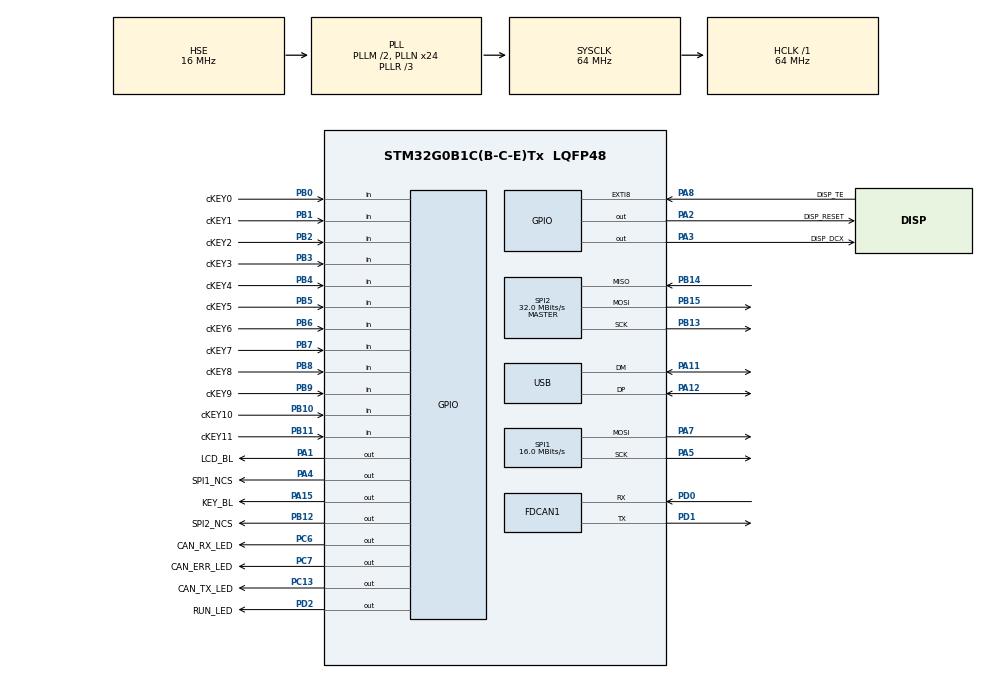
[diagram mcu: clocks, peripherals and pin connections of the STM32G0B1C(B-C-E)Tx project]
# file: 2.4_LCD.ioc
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Dma.Request0=SPI1_TX
Dma.Request1=SPI2_RX
Dma.Request2=SPI2_TX
Dma.SPI1_TX.0.Direction=DMA_MEMORY_TO_PERIPH
Dma.SPI1_TX.0.EventEnable=DISABLE
Dma.SPI1_TX.0.Instance=DMA1_Channel1
Dma.SPI1_TX.0.MemDataAlignment=DMA_MDATAALIGN_HALFWORD
Dma.SPI1_TX.0.MemInc=DMA_MINC_ENABLE
Dma.SPI1_TX.0.Mode=DMA_NORMAL
Dma.SPI1_TX.0.PeriphDataAlignment=DMA_PDATAALIGN_HALFWORD
Dma.SPI1_TX.0.PeriphInc=DMA_PINC_DISABLE
Dma.SPI1_TX.0.Polarity=HAL_DMAMUX_REQ_GEN_RISING
Dma.SPI1_TX.0.Priority=DMA_PRIORITY_HIGH
Dma.SPI1_TX.0.RequestNumber=1
Dma.SPI1_TX.0.SignalID=NONE
Dma.SPI1_TX.0.SyncEnable=DISABLE
Dma.SPI1_TX.0.SyncPolarity=HAL_DMAMUX_SYNC_NO_EVENT
Dma.SPI1_TX.0.SyncRequestNumber=1
Dma.SPI1_TX.0.SyncSignalID=NONE
Dma.SPI2_RX.1.Direction=DMA_PERIPH_TO_MEMORY
Dma.SPI2_RX.1.EventEnable=DISABLE
Dma.SPI2_RX.1.Instance=DMA1_Channel2
Dma.SPI2_RX.1.MemDataAlignment=DMA_MDATAALIGN_BYTE
Dma.SPI2_RX.1.MemInc=DMA_MINC_ENABLE
Dma.SPI2_RX.1.Mode=DMA_NORMAL
Dma.SPI2_RX.1.PeriphDataAlignment=DMA_PDATAALIGN_BYTE
Dma.SPI2_RX.1.PeriphInc=DMA_PINC_DISABLE
Dma.SPI2_RX.1.Polarity=HAL_DMAMUX_REQ_GEN_RISING
Dma.SPI2_RX.1.Priority=DMA_PRIORITY_VERY_HIGH
Dma.SPI2_RX.1.RequestNumber=1
Dma.SPI2_RX.1.SignalID=NONE
Dma.SPI2_RX.1.SyncEnable=DISABLE
Dma.SPI2_RX.1.SyncPolarity=HAL_DMAMUX_SYNC_NO_EVENT
Dma.SPI2_RX.1.SyncRequestNumber=1
Dma.SPI2_RX.1.SyncSignalID=NONE
Dma.SPI2_TX.2.Direction=DMA_MEMORY_TO_PERIPH
Dma.SPI2_TX.2.EventEnable=DISABLE
Dma.SPI2_TX.2.Instance=DMA1_Channel3
Dma.SPI2_TX.2.MemDataAlignment=DMA_MDATAALIGN_BYTE
Dma.SPI2_TX.2.MemInc=DMA_MINC_ENABLE
Dma.SPI2_TX.2.Mode=DMA_NORMAL
Dma.SPI2_TX.2.PeriphDataAlignment=DMA_PDATAALIGN_BYTE
Dma.SPI2_TX.2.PeriphInc=DMA_PINC_DISABLE
Dma.SPI2_TX.2.Polarity=HAL_DMAMUX_REQ_GEN_RISING
Dma.SPI2_TX.2.Priority=DMA_PRIORITY_MEDIUM
Dma.SPI2_TX.2.RequestNumber=1
Dma.SPI2_TX.2.SignalID=NONE
Dma.SPI2_TX.2.SyncEnable=DISABLE
Dma.SPI2_TX.2.SyncPolarity=HAL_DMAMUX_SYNC_NO_EVENT
Dma.SPI2_TX.2.SyncRequestNumber=1
Dma.SPI2_TX.2.SyncSignalID=NONE
FDCAN1.AutoRetransmission=ENABLE
FDCAN1.CalculateBaudRateNominal=500000
FDCAN1.CalculateTimeBitNominal=2000
FDCAN1.CalculateTimeQuantumNominal=62.5
FDCAN1.DataPrescaler=1
FDCAN1.NominalPrescaler=4
FDCAN1.NominalSyncJumpWidth=4
FDCAN1.NominalTimeSeg1=27
FDCAN1.NominalTimeSeg2=4
FDCAN1.StdFiltersNbr=1
Mcu.Family=STM32G0
Mcu.Name=STM32G0B1C(B-C-E)Tx
Mcu.Package=LQFP48
NVIC.DMA1_Channel1_IRQn=true\:0\:0\:false\:false\:true\:false\:true\:true
NVIC.DMA1_Channel2_3_IRQn=true\:0\:0\:false\:false\:true\:false\:true\:true
NVIC.EXTI4_15_IRQn=true\:0\:0\:false\:false\:true\:true\:true\:true
NVIC.TIM16_FDCAN_IT0_IRQn=true\:0\:0\:false\:false\:true\:true\:true\:true
NVIC.USB_UCPD1_2_IRQn=true\:0\:0\:false\:false\:true\:true\:true\:true
PA1.GPIO_Label=LCD_BL
PA1.Signal=GPIO_Output
PA11\ [PA9].Mode=Device
PA11\ [PA9].Signal=USB_DM
PA12\ [PA10].Mode=Device
PA12\ [PA10].Signal=USB_DP
PA13.Mode=Serial_Wire
PA13.Signal=SYS_SWDIO
PA14-BOOT0.Mode=Serial_Wire
PA14-BOOT0.Signal=SYS_SWCLK
PA15.GPIO_Label=KEY_BL
PA15.PinState=GPIO_PIN_RESET
PA15.Signal=GPIO_Output
PA2.GPIO_Label=DISP_RESET
PA2.PinState=GPIO_PIN_SET
PA2.Signal=GPIO_Output
PA3.GPIO_Label=DISP_DCX
PA3.GPIO_Speed=GPIO_SPEED_FREQ_VERY_HIGH
PA3.Signal=GPIO_Output
PA4.GPIO_Label=SPI1_NCS
PA4.GPIO_Speed=GPIO_SPEED_FREQ_VERY_HIGH
PA4.PinState=GPIO_PIN_SET
PA4.Signal=GPIO_Output
PA5.GPIO_Speed=GPIO_SPEED_FREQ_VERY_HIGH
PA5.Mode=TX_Only_Simplex_Unidirect_Master
PA5.PinState=GPIO_PIN_RESET
PA5.Signal=SPI1_SCK
PA7.GPIO_Speed=GPIO_SPEED_FREQ_VERY_HIGH
PA7.Mode=TX_Only_Simplex_Unidirect_Master
PA7.Signal=SPI1_MOSI
PA8.GPIO_Label=DISP_TE
PA8.Signal=GPXTI8
PB0.GPIO_Label=cKEY0
PB0.Signal=GPIO_Input
PB1.GPIO_Label=cKEY1
PB1.Signal=GPIO_Input
PB10.GPIO_Label=cKEY10
PB10.Signal=GPIO_Input
PB11.GPIO_Label=cKEY11
PB11.Signal=GPIO_Input
PB12.GPIO_Label=SPI2_NCS
PB12.GPIO_Speed=GPIO_SPEED_FREQ_VERY_HIGH
PB12.PinState=GPIO_PIN_SET
PB12.Signal=GPIO_Output
PB13.GPIO_Speed=GPIO_SPEED_FREQ_VERY_HIGH
PB13.Mode=Full_Duplex_Master
PB13.Signal=SPI2_SCK
PB14.Mode=Full_Duplex_Master
PB14.Signal=SPI2_MISO
PB15.GPIO_Speed=GPIO_SPEED_FREQ_VERY_HIGH
PB15.Mode=Full_Duplex_Master
PB15.Signal=SPI2_MOSI
PB2.GPIO_Label=cKEY2
PB2.Signal=GPIO_Input
PB3.GPIO_Label=cKEY3
PB3.Signal=GPIO_Input
PB4.GPIO_Label=cKEY4
PB4.Signal=GPIO_Input
PB5.GPIO_Label=cKEY5
PB5.Signal=GPIO_Input
PB6.GPIO_Label=cKEY6
PB6.Signal=GPIO_Input
PB7.GPIO_Label=cKEY7
PB7.Signal=GPIO_Input
PB8.GPIO_Label=cKEY8
PB8.Signal=GPIO_Input
PB9.GPIO_Label=cKEY9
PB9.Signal=GPIO_Input
PC13.GPIO_Label=CAN_TX_LED
PC13.PinState=GPIO_PIN_SET
PC13.Signal=GPIO_Output
PC6.GPIO_Label=CAN_RX_LED
PC6.PinState=GPIO_PIN_SET
PC6.Signal=GPIO_Output
PC7.GPIO_Label=CAN_ERR_LED
PC7.PinState=GPIO_PIN_SET
PC7.Signal=GPIO_Output
PD0.Mode=FDCAN_Activate
PD0.Signal=FDCAN1_RX
PD1.Mode=FDCAN_Activate
PD1.Signal=FDCAN1_TX
PD2.GPIO_Label=RUN_LED
PD2.PinState=GPIO_PIN_SET
PD2.Signal=GPIO_Output
PF0-OSC_IN\ (PF0).Mode=HSE-External-Oscillator
PF0-OSC_IN\ (PF0).Signal=RCC_OSC_IN
PF1-OSC_OUT\ (PF1).Mode=HSE-External-Oscillator
PF1-OSC_OUT\ (PF1).Signal=RCC_OSC_OUT
ProjectManager.HeapSize=0x200
ProjectManager.StackSize=0x800
ProjectManager.TargetToolchain=CMake
RCC.ADCFreq_Value=64000000
RCC.AHBFreq_Value=64000000
RCC.CortexFreq_Value=64000000
RCC.EXTERNAL_CLOCK_VALUE=48000
RCC.HCLKFreq_Value=64000000
RCC.HSE_VALUE=16000000
RCC.HSI48_VALUE=48000000
RCC.HSI_VALUE=16000000
RCC.LSE_VALUE=32768
RCC.PLLM=RCC_PLLM_DIV2
RCC.PLLN=24
RCC.PLLQ=RCC_PLLQ_DIV4
RCC.PLLR=RCC_PLLR_DIV3
RCC.PLLSourceVirtual=RCC_PLLSOURCE_HSE
RCC.SYSCLKFreq_VALUE=64000000
RCC.SYSCLKSource=RCC_SYSCLKSOURCE_PLLCLK
RCC.USBCLockSelection=RCC_USBCLKSOURCE_PLL
RCC.USBFreq_Value=48000000
RCC.VCOOutputFreq_Value=192000000
SPI1.BaudRatePrescaler=SPI_BAUDRATEPRESCALER_4
SPI1.CalculateBaudRate=16.0 MBits/s
SPI1.DataSize=SPI_DATASIZE_8BIT
SPI1.Direction=SPI_DIRECTION_2LINES
SPI1.Mode=SPI_MODE_MASTER
SPI1.VirtualType=VM_MASTER
SPI2.BaudRatePrescaler=SPI_BAUDRATEPRESCALER_2
SPI2.CalculateBaudRate=32.0 MBits/s
SPI2.DataSize=SPI_DATASIZE_8BIT
SPI2.Direction=SPI_DIRECTION_2LINES
SPI2.Mode=SPI_MODE_MASTER
SPI2.VirtualType=VM_MASTER
STMicroelectronics.X-CUBE-TOUCHGFX.4.26.1.ApplicationCcGraphicsJjApplication=TouchGFXOoGenerator
STMicroelectronics.X-CUBE-TOUCHGFX.4.26.1.tgfx_block_size=9600
STMicroelectronics.X-CUBE-TOUCHGFX.4.26.1.tgfx_buffering_strategy=Partial
STMicroelectronics.X-CUBE-TOUCHGFX.4.26.1.tgfx_custom_height=320
STMicroelectronics.X-CUBE-TOUCHGFX.4.26.1.tgfx_custom_width=240
STMicroelectronics.X-CUBE-TOUCHGFX.4.26.1.tgfx_datareader=Enabled
STMicroelectronics.X-CUBE-TOUCHGFX.4.26.1.tgfx_datareader_dma_transfersize=16
STMicroelectronics.X-CUBE-TOUCHGFX.4.26.1.tgfx_datareader_mem_size=0x00800000
STMicroelectronics.X-CUBE-TOUCHGFX.4.26.1.tgfx_number_of_blocks=2
STMicroelectronics.X-CUBE-TOUCHGFX.4.26.1_IsPackSelfContextualization=true
USB_DEVICE.CLASS_NAME_FS=CDC
USB_DEVICE.VirtualMode=Cdc
USB_DEVICE.VirtualModeFS=Cdc_FS
VP_CRC_VS_CRC.Mode=CRC_Activate
VP_STMicroelectronics.X-CUBE-TOUCHGFX_VS_GraphicsJjApplication_4.26.1.Mode=GraphicsJjApplication
VP_SYS_VS_DBSignals.Mode=DisableDeadBatterySignals
VP_USB_DEVICE_VS_USB_DEVICE_CDC_FS.Mode=CDC_FS
board=custom

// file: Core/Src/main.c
/* USER CODE BEGIN Header */
/**
  ******************************************************************************
  * @file           : main.c
  * @brief          : Main program body
  ******************************************************************************
  * @attention
  *
  * Copyright (c) 2026 STMicroelectronics.
  * All rights reserved.
  *
  * This software is licensed under terms that can be found in the LICENSE file
  * in the root directory of this software component.
  * If no LICENSE file comes with this software, it is provided AS-IS.
  *
  ******************************************************************************
  */
/* USER CODE END Header */
#include "main.h"
#include "crc.h"
#include "dma.h"
#include "fdcan.h"
#include "spi.h"
#include "usb_device.h"
#include "gpio.h"
#include "app_touchgfx.h"

/* USER CODE BEGIN Includes */
#include <stdio.h>
#include "dbg_console.h"
#include "display_driver.h"
#include "flash_driver.h"
#include "app_main.h"
/* USER CODE END Includes */

void SystemClock_Config(void);

int main(void)
{

  /* MCU Configuration--------------------------------------------------------*/

  /* Reset of all peripherals, Initializes the Flash interface and the Systick. */
  HAL_Init();

  /* Configure the system clock */
  SystemClock_Config();

  /* Initialize all configured peripherals */
  MX_GPIO_Init();
  MX_DMA_Init();
  MX_FDCAN1_Init();
  MX_SPI1_Init();
  MX_SPI2_Init();
  MX_CRC_Init();
  MX_USB_Device_Init();
  MX_TouchGFX_Init();
  /* USER CODE BEGIN 2 */
  dbg_console_init();
  printf("\r\n[2.4_LCD] boot. SYSCLK=%luHz\r\n", SystemCoreClock);

  if (FLASH_DRIVER_Init() == 0)
  {
    /* MX25L6433F 무응답 (JEDEC ID 불일치) - 배선/전원 확인 필요.
     * UI 에셋이 이 플래시에 있으므로 더 진행해도 의미가 없다. */
    printf("[2.4_LCD] SPI flash JEDEC=0x%06lX (expected 0xC22017)\r\n",
           (unsigned long)FLASH_DRIVER_ReadJEDEC());
    Error_Handler();
  }
  LCD_Init();
  AppMain_Init();   /* CAN 시작 + 키 백라이트 ON (주기 처리는 아래 while 루프의 AppMain_Poll) */
  /* USER CODE END 2 */

  /* Infinite loop */
  while (1)
  {

  MX_TouchGFX_Process();
    /* USER CODE BEGIN 3 */
    /* MX_TouchGFX_Process()는 VSYNC가 없으면 즉시 리턴하는 폴링 함수라
     * 이 루프는 계속 돈다. 인터럽트가 큐에 넣은 키/CAN 데이터를 여기서
     * 꺼내 처리한다 (최상단 애플리케이션 함수). */
    AppMain_Poll();
  }
  /* USER CODE END 3 */
}

void SystemClock_Config(void)
{
  RCC_OscInitTypeDef RCC_OscInitStruct = {0};
  RCC_ClkInitTypeDef RCC_ClkInitStruct = {0};

  /** Configure the main internal regulator output voltage
  */
  HAL_PWREx_ControlVoltageScaling(PWR_REGULATOR_VOLTAGE_SCALE1);

  /** Initializes the RCC Oscillators according to the specified parameters
  * in the RCC_OscInitTypeDef structure.
  */
  RCC_OscInitStruct.OscillatorType = RCC_OSCILLATORTYPE_HSE;
  RCC_OscInitStruct.HSEState = RCC_HSE_ON;
  RCC_OscInitStruct.PLL.PLLState = RCC_PLL_ON;
  RCC_OscInitStruct.PLL.PLLSource = RCC_PLLSOURCE_HSE;
  RCC_OscInitStruct.PLL.PLLM = RCC_PLLM_DIV2;
  RCC_OscInitStruct.PLL.PLLN = 24;
  RCC_OscInitStruct.PLL.PLLP = RCC_PLLP_DIV2;
  RCC_OscInitStruct.PLL.PLLQ = RCC_PLLQ_DIV4;
  RCC_OscInitStruct.PLL.PLLR = RCC_PLLR_DIV3;
  if (HAL_RCC_OscConfig(&RCC_OscInitStruct) != HAL_OK)
  {
    Error_Handler();
  }

  /** Initializes the CPU, AHB and APB buses clocks
  */
  RCC_ClkInitStruct.ClockType = RCC_CLOCKTYPE_HCLK|RCC_CLOCKTYPE_SYSCLK
                              |RCC_CLOCKTYPE_PCLK1;
  RCC_ClkInitStruct.SYSCLKSource = RCC_SYSCLKSOURCE_PLLCLK;
  RCC_ClkInitStruct.AHBCLKDivider = RCC_SYSCLK_DIV1;
  RCC_ClkInitStruct.APB1CLKDivider = RCC_HCLK_DIV1;

  if (HAL_RCC_ClockConfig(&RCC_ClkInitStruct, FLASH_LATENCY_2) != HAL_OK)
  {
    Error_Handler();
  }
}

void Error_Handler(void)
{
  __disable_irq();
  while (1)
  {
  }
}
